VERSION "created by canmatrix"

NS_ :

BS_:

BU_: User ADM_PC_LL25 ADM_PC_BC25 ADM_PC_BP25 ADM_PC_BI25

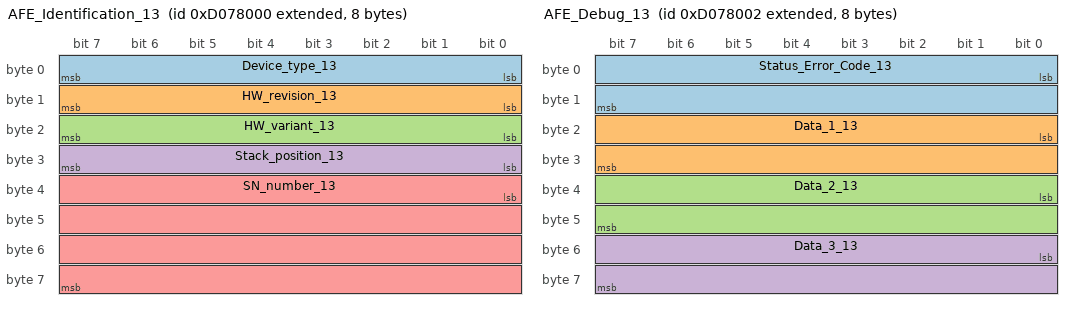
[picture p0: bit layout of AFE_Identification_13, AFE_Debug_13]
BO_ 2366078976 AFE_Identification_13: 8 ADM_PC_BP25
 SG_ Device_type_13 : 0|8@1+ (1,0) [0|255] "" Vector__XXX
 SG_ HW_revision_13 : 8|8@1+ (1,0) [0|255] "" Vector__XXX
 SG_ HW_variant_13 : 16|8@1+ (1,0) [0|255] "" Vector__XXX
 SG_ Stack_position_13 : 24|8@1+ (1,0) [0|255] "" Vector__XXX
 SG_ SN_number_13 : 32|32@1+ (1,0) [0|4294967295] "" Vector__XXX

BO_ 2366078977 AFE_FwInfo_13: 8 ADM_PC_BP25
 SG_ FW_info_mux_13 M : 56|8@1+ (1,0) [0|255] "" Vector__XXX
 SG_ FW_revision_0_13 m0 : 0|8@1+ (1,0) [0|255] "" Vector__XXX
 SG_ FW_revision_1_13 m0 : 8|8@1+ (1,0) [0|255] "" Vector__XXX
 SG_ FW_revision_2_13 m0 : 16|8@1+ (1,0) [0|255] "" Vector__XXX
 SG_ FW_revision_3_13 m0 : 24|8@1+ (1,0) [0|255] "" Vector__XXX
 SG_ FW_revision_4_13 m0 : 32|8@1+ (1,0) [0|255] "" Vector__XXX
 SG_ FW_revision_5_13 m0 : 40|8@1+ (1,0) [0|255] "" Vector__XXX
 SG_ FW_revision_6_13 m0 : 48|8@1+ (1,0) [0|255] "" Vector__XXX
 SG_ FW_revision_7_13 m1 : 0|8@1+ (1,0) [0|255] "" Vector__XXX
 SG_ FW_revision_8_13 m1 : 8|8@1+ (1,0) [0|255] "" Vector__XXX
 SG_ FW_revision_9_13 m1 : 16|8@1+ (1,0) [0|255] "" Vector__XXX
 SG_ FW_revision_10_13 m1 : 24|8@1+ (1,0) [0|255] "" Vector__XXX
 SG_ FW_revision_11_13 m1 : 32|8@1+ (1,0) [0|255] "" Vector__XXX
 SG_ FW_revision_12_13 m1 : 40|8@1+ (1,0) [0|255] "" Vector__XXX
 SG_ FW_revision_13_13 m1 : 48|8@1+ (1,0) [0|255] "" Vector__XXX
 SG_ FW_datecode_0_13 m2 : 0|8@1+ (1,0) [0|255] "" Vector__XXX
 SG_ FW_datecode_1_13 m2 : 8|8@1+ (1,0) [0|255] "" Vector__XXX
 SG_ FW_datecode_2_13 m2 : 16|8@1+ (1,0) [0|255] "" Vector__XXX
 SG_ FW_datecode_3_13 m2 : 24|8@1+ (1,0) [0|255] "" Vector__XXX
 SG_ FW_datecode_4_13 m2 : 32|8@1+ (1,0) [0|255] "" Vector__XXX
 SG_ FW_datecode_5_13 m2 : 40|8@1+ (1,0) [0|255] "" Vector__XXX
 SG_ FW_datecode_6_13 m2 : 48|8@1+ (1,0) [0|255] "" Vector__XXX
 SG_ FW_datecode_7_13 m3 : 0|8@1+ (1,0) [0|255] "" Vector__XXX
 SG_ FW_datecode_8_13 m3 : 8|8@1+ (1,0) [0|255] "" Vector__XXX
 SG_ FW_datecode_9_13 m3 : 16|8@1+ (1,0) [0|255] "" Vector__XXX
 SG_ FW_datecode_10_13 m3 : 24|8@1+ (1,0) [0|255] "" Vector__XXX
 SG_ FW_datecode_11_13 m3 : 32|8@1+ (1,0) [0|255] "" Vector__XXX
 SG_ FW_datecode_12_13 m3 : 40|8@1+ (1,0) [0|255] "" Vector__XXX
 SG_ FW_datecode_13_13 m3 : 48|8@1+ (1,0) [0|255] "" Vector__XXX

BO_ 2366078989 _AFE_Boot_FwInfo_13: 8 ADM_PC_BP25
 SG_ Boot_FW_info_mux_13 M : 56|8@1+ (1,0) [0|255] "" Vector__XXX
 SG_ FW_revision_0_13 m0 : 0|8@1+ (1,0) [0|255] "" Vector__XXX
 SG_ FW_revision_1_13 m0 : 8|8@1+ (1,0) [0|255] "" Vector__XXX
 SG_ FW_revision_2_13 m0 : 16|8@1+ (1,0) [0|255] "" Vector__XXX
 SG_ FW_revision_3_13 m0 : 24|8@1+ (1,0) [0|255] "" Vector__XXX
 SG_ FW_revision_4_13 m0 : 32|8@1+ (1,0) [0|255] "" Vector__XXX
 SG_ FW_revision_5_13 m0 : 40|8@1+ (1,0) [0|255] "" Vector__XXX
 SG_ FW_revision_6_13 m0 : 48|8@1+ (1,0) [0|255] "" Vector__XXX
 SG_ FW_revision_7_13 m1 : 0|8@1+ (1,0) [0|255] "" Vector__XXX
 SG_ FW_revision_8_13 m1 : 8|8@1+ (1,0) [0|255] "" Vector__XXX
 SG_ FW_revision_9_13 m1 : 16|8@1+ (1,0) [0|255] "" Vector__XXX
 SG_ FW_revision_10_13 m1 : 24|8@1+ (1,0) [0|255] "" Vector__XXX
 SG_ FW_revision_11_13 m1 : 32|8@1+ (1,0) [0|255] "" Vector__XXX
 SG_ FW_revision_12_13 m1 : 40|8@1+ (1,0) [0|255] "" Vector__XXX
 SG_ FW_revision_13_13 m1 : 48|8@1+ (1,0) [0|255] "" Vector__XXX
 SG_ FW_datecode_0_13 m2 : 0|8@1+ (1,0) [0|255] "" Vector__XXX
 SG_ FW_datecode_1_13 m2 : 8|8@1+ (1,0) [0|255] "" Vector__XXX
 SG_ FW_datecode_2_13 m2 : 16|8@1+ (1,0) [0|255] "" Vector__XXX
 SG_ FW_datecode_3_13 m2 : 24|8@1+ (1,0) [0|255] "" Vector__XXX
 SG_ FW_datecode_4_13 m2 : 32|8@1+ (1,0) [0|255] "" Vector__XXX
 SG_ FW_datecode_5_13 m2 : 40|8@1+ (1,0) [0|255] "" Vector__XXX
 SG_ FW_datecode_6_13 m2 : 48|8@1+ (1,0) [0|255] "" Vector__XXX
 SG_ FW_datecode_7_13 m3 : 0|8@1+ (1,0) [0|255] "" Vector__XXX
 SG_ FW_datecode_8_13 m3 : 8|8@1+ (1,0) [0|255] "" Vector__XXX
 SG_ FW_datecode_9_13 m3 : 16|8@1+ (1,0) [0|255] "" Vector__XXX
 SG_ FW_datecode_10_13 m3 : 24|8@1+ (1,0) [0|255] "" Vector__XXX
 SG_ FW_datecode_11_13 m3 : 32|8@1+ (1,0) [0|255] "" Vector__XXX
 SG_ FW_datecode_12_13 m3 : 40|8@1+ (1,0) [0|255] "" Vector__XXX
 SG_ FW_datecode_13_13 m3 : 48|8@1+ (1,0) [0|255] "" Vector__XXX

BO_ 2366078978 AFE_Debug_13: 8 ADM_PC_BP25
 SG_ Status_Error_Code_13 : 0|16@1+ (1,0) [0|65535] "" Vector__XXX
 SG_ Data_1_13 : 16|16@1+ (1,0) [0|65535] "" Vector__XXX
 SG_ Data_2_13 : 32|16@1+ (1,0) [0|65535] "" Vector__XXX
 SG_ Data_3_13 : 48|16@1+ (1,0) [0|65535] "" Vector__XXX

BO_ 2366078983 AFE_Status_13: 8 ADM_PC_BP25
 SG_ Running_13 : 0|1@1+ (1,0) [0|1] "" Vector__XXX
 SG_ PWM_13 : 1|1@1+ (1,0) [0|1] "" Vector__XXX
 SG_ Current_dc_loop_mode_13 : 2|1@1+ (1,0) [0|1] "" Vector__XXX
 SG_ Current_ac_loop_mode_13 : 3|1@1+ (1,0) [0|1] "" Vector__XXX
 SG_ Buck_13 : 5|1@1+ (1,0) [0|1] "" Vector__XXX
 SG_ Boost_13 : 6|1@1+ (1,0) [0|1] "" Vector__XXX
 SG_ Precharge_dc_buck_mode_13 : 7|1@1+ (1,0) [0|1] "" Vector__XXX
 SG_ Precharge_dc_boost_mode_13 : 8|1@1+ (1,0) [0|1] "" Vector__XXX
 SG_ Rectifier_3ph_13 : 9|1@1+ (1,0) [0|1] "" Vector__XXX
 SG_ Stack_mode_13 : 10|1@1+ (1,0) [0|1] "" Vector__XXX
 SG_ Master_13 : 11|1@1+ (1,0) [0|1] "" Vector__XXX
 SG_ Slave_13 : 12|1@1+ (1,0) [0|1] "" Vector__XXX
 SG_ Inverter_1ph_13 : 13|1@1+ (1,0) [0|1] "" Vector__XXX
 SG_ Boost_Neutral_13 : 14|1@1+ (1,0) [0|1] "" Vector__XXX
 SG_ Rectifier_1ph_13 : 15|1@1+ (1,0) [0|1] "" Vector__XXX
 SG_ Inverter_3ph_13 : 16|1@1+ (1,0) [0|1] "" Vector__XXX
 SG_ Ready_13 : 17|1@1+ (1,0) [0|1] "" Vector__XXX
 SG_ Inverter_1ph_Sync_13 : 18|1@1+ (1,0) [0|1] "" Vector__XXX
 SG_ Neutral_13 : 19|1@1+ (1,0) [0|1] "" Vector__XXX
 SG_ Rectifier_1ph_Buck_13 : 20|1@1+ (1,0) [0|1] "" Vector__XXX
 SG_ Inverter_1ph_Boost_13 : 21|1@1+ (1,0) [0|1] "" Vector__XXX
 SG_ Rectifier_distributed_13 : 22|1@1+ (1,0) [0|1] "" Vector__XXX
 SG_ MPPT_buck_13 : 23|1@1+ (1,0) [0|1] "" Vector__XXX
 SG_ MPPT_boost_13 : 24|1@1+ (1,0) [0|1] "" Vector__XXX
 SG_ Buck_2p_float_13 : 25|1@1+ (1,0) [0|1] "" Vector__XXX
 SG_ Inverter_1ph_Distributed_13 : 26|1@1+ (1,0) [0|1] "" Vector__XXX

BO_ 2366078982 AFE_Faults_13: 3 ADM_PC_BP25
 SG_ Protection_trip_internal_13 : 0|1@1+ (1,0) [0|1] "" Vector__XXX
 SG_ Protection_trip_external_13 : 1|1@1+ (1,0) [0|1] "" Vector__XXX
 SG_ Phase_U_overcurrent_13 : 2|1@1+ (1,0) [0|1] "" Vector__XXX
 SG_ Phase_U_overvoltage_13 : 3|1@1+ (1,0) [0|1] "" Vector__XXX
 SG_ Phase_U_undervoltage_13 : 4|1@1+ (1,0) [0|1] "" Vector__XXX
 SG_ Phase_V_overvoltage_13 : 5|1@1+ (1,0) [0|1] "" Vector__XXX
 SG_ Phase_V_undervoltage_13 : 6|1@1+ (1,0) [0|1] "" Vector__XXX
 SG_ Phase_V_overcurrent_13 : 7|1@1+ (1,0) [0|1] "" Vector__XXX
 SG_ Phase_W_overvoltage_13 : 8|1@1+ (1,0) [0|1] "" Vector__XXX
 SG_ Phase_W_undervoltage_13 : 9|1@1+ (1,0) [0|1] "" Vector__XXX
 SG_ Phase_W_overcurrent_13 : 10|1@1+ (1,0) [0|1] "" Vector__XXX
 SG_ DC_undervoltage_13 : 11|1@1+ (1,0) [0|1] "" Vector__XXX
 SG_ DC_overvoltage_13 : 12|1@1+ (1,0) [0|1] "" Vector__XXX
 SG_ MOSFET_overtemperature_13 : 13|1@1+ (1,0) [0|1] "" Vector__XXX
 SG_ Inductor_overtemperature_13 : 14|1@1+ (1,0) [0|1] "" Vector__XXX
 SG_ Keep_Alive_not_served_13 : 15|1@1+ (1,0) [0|1] "" Vector__XXX
 SG_ PLL_not_locked_13 : 16|1@1+ (1,0) [0|1] "" Vector__XXX
 SG_ NFO_13 : 20|1@1+ (1,0) [0|1] "" Vector__XXX
 SG_ Measurement_system_failure_13 : 21|1@1+ (1,0) [0|1] "" Vector__XXX
 SG_ EEPROM_failure_13 : 22|1@1+ (1,0) [0|1] "" Vector__XXX
 SG_ System_13 : 23|1@1+ (1,0) [0|1] "" Vector__XXX

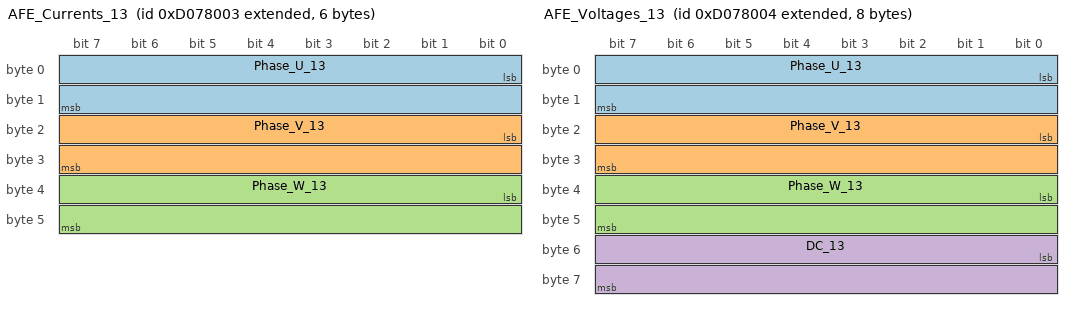
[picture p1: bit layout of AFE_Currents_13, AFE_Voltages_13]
BO_ 2366078979 AFE_Currents_13: 6 ADM_PC_BP25
 SG_ Phase_U_13 : 0|16@1- (0.01,0) [-327.68|327.67] "A" Vector__XXX
 SG_ Phase_V_13 : 16|16@1- (0.01,0) [-327.68|327.67] "A" Vector__XXX
 SG_ Phase_W_13 : 32|16@1- (0.01,0) [-327.68|327.67] "A" Vector__XXX

BO_ 2366078992 AFE_DC_Bus_current_13: 2 ADM_PC_BP25
 SG_ Bus_current_13 : 0|16@1- (0.01,0) [-327.68|327.67] "A" Vector__XXX

BO_ 2366078990 _AFE_Broadcast_13: 8 ADM_PC_BP25
 SG_ Diagnostics_Index_13 M : 56|8@1+ (1,0) [0|255] "" Vector__XXX
 SG_ Phase_U_13 m1 : 8|16@1- (0.01,0) [-327.68|327.67] "A" ADM_PC_BP25
 SG_ Phase_V_13 m1 : 24|16@1- (0.01,0) [-327.68|327.67] "A" ADM_PC_BP25
 SG_ Phase_W_13 m1 : 40|16@1- (0.01,0) [-327.68|327.67] "A" ADM_PC_BP25
 SG_ Stack_position_13 : 0|5@1+ (1,0) [0|31] "" ADM_PC_BP25
 SG_ Group_ID_13 : 5|3@1+ (1,0) [0|7] "" ADM_PC_BP25

BO_ 2366078980 AFE_Voltages_13: 8 ADM_PC_BP25
 SG_ Phase_U_13 : 0|16@1- (0.1,0) [-3276.8|3276.7] "V" Vector__XXX
 SG_ Phase_V_13 : 16|16@1- (0.1,0) [-3276.8|3276.7] "V" Vector__XXX
 SG_ Phase_W_13 : 32|16@1- (0.1,0) [-3276.8|3276.7] "V" Vector__XXX
 SG_ DC_13 : 48|16@1- (0.1,0) [-3276.8|3276.7] "V" Vector__XXX

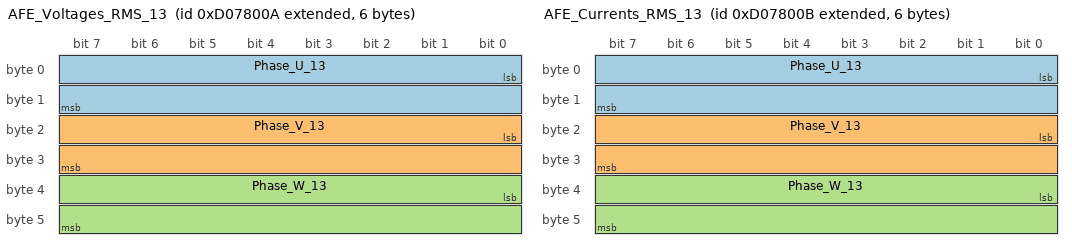
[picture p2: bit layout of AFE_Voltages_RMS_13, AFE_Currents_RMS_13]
BO_ 2366078986 AFE_Voltages_RMS_13: 6 ADM_PC_BP25
 SG_ Phase_U_13 : 0|16@1+ (0.1,0) [0|6553.5] "V" Vector__XXX
 SG_ Phase_V_13 : 16|16@1+ (0.1,0) [0|6553.5] "V" Vector__XXX
 SG_ Phase_W_13 : 32|16@1+ (0.1,0) [0|6553.5] "V" Vector__XXX

BO_ 2366078987 AFE_Currents_RMS_13: 6 ADM_PC_BP25
 SG_ Phase_U_13 : 0|16@1+ (0.01,0) [0.00|655.35] "A" Vector__XXX
 SG_ Phase_V_13 : 16|16@1+ (0.01,0) [0.00|655.35] "A" Vector__XXX
 SG_ Phase_W_13 : 32|16@1+ (0.01,0) [0.00|655.35] "A" Vector__XXX

BO_ 2366078988 AFE_Mains_13: 4 ADM_PC_BP25
 SG_ Frequency_13 : 0|16@1+ (0.01,0) [0.00|655.35] "Hz" Vector__XXX
 SG_ Phase_13 : 16|16@1- (0.1,0) [-3276.8|3276.7] "Deg." Vector__XXX

BO_ 2366078981 AFE_Temperatures_13: 4 ADM_PC_BP25
 SG_ Temp_Bridge_13 : 0|16@1- (0.01,0) [-327.68|327.67] "°C" Vector__XXX
 SG_ Temp_Inductors_13 : 16|16@1- (0.01,0) [-327.68|327.67] "°C" Vector__XXX

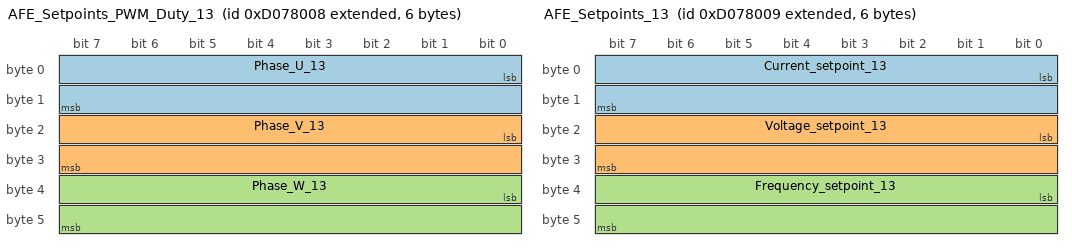
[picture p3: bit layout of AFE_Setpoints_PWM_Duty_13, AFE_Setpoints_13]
BO_ 2366078984 AFE_Setpoints_PWM_Duty_13: 6 ADM_PC_BP25
 SG_ Phase_U_13 : 0|16@1+ (0.001525902,0) [0E-009|99.999987570] "%" Vector__XXX
 SG_ Phase_V_13 : 16|16@1+ (0.001525902,0) [0E-009|99.999987570] "%" Vector__XXX
 SG_ Phase_W_13 : 32|16@1+ (0.001525902,0) [0E-009|99.999987570] "%" Vector__XXX

BO_ 2366078985 AFE_Setpoints_13: 6 ADM_PC_BP25
 SG_ Current_setpoint_13 : 0|16@1- (0.01,0) [-327.68|327.67] "A" Vector__XXX
 SG_ Voltage_setpoint_13 : 16|16@1+ (0.1,0) [0|6553.5] "V" Vector__XXX
 SG_ Frequency_setpoint_13 : 32|16@1+ (0.01,0) [0.00|655.35] "Hz" Vector__XXX

BO_ 2366046304 AFE_Keep_Alive_13: 1 User
 SG_ Keep_Alive_Enable_13 : 0|1@1+ (1,0) [0|1] "" ADM_PC_BP25

BO_ 2366046272 AFE_Mode_Control_13: 8 User
 SG_ Converter_ON_13 : 0|1@1+ (1,0) [0|1] "" ADM_PC_BP25
 SG_ PWM_ON_13 : 1|1@1+ (1,0) [0|1] "" ADM_PC_BP25
 SG_ DC_Current_feedback_ON_13 : 2|1@1+ (1,0) [0|1] "" ADM_PC_BP25
 SG_ AC_Current_feedback_ON_13 : 3|1@1+ (1,0) [0|1] "" ADM_PC_BP25
 SG_ Buck_ON_13 : 5|1@1+ (1,0) [0|1] "" ADM_PC_BP25
 SG_ Boost_ON_13 : 6|1@1+ (1,0) [0|1] "" ADM_PC_BP25
 SG_ Rectifier_3ph_ON_13 : 9|1@1+ (1,0) [0|1] "" ADM_PC_BP25
 SG_ Inverter_1ph_ON_13 : 10|1@1+ (1,0) [0|1] "" ADM_PC_BP25
 SG_ Rectifier_1ph_ON_13 : 11|1@1+ (1,0) [0|1] "" ADM_PC_BP25
 SG_ Boost_Neutral_ON_13 : 12|1@1+ (1,0) [0|1] "" ADM_PC_BP25
 SG_ Inverter_3ph_ON_13 : 13|1@1+ (1,0) [0|1] "" ADM_PC_BP25
 SG_ Inverter_1ph_Sync_ON_13 : 14|1@1+ (1,0) [0|1] "" ADM_PC_BP25
 SG_ Neutral_ON_13 : 15|1@1+ (1,0) [0|1] "" ADM_PC_BP25
 SG_ Rectifier_1ph_Buck_ON_13 : 16|1@1+ (1,0) [0|1] "" ADM_PC_BP25
 SG_ Inverter_1ph_Boost_ON_13 : 17|1@1+ (1,0) [0|1] "" ADM_PC_BP25
 SG_ Rectifier_Distributed_ON_13 : 18|1@1+ (1,0) [0|1] "" ADM_PC_BP25
 SG_ MPPT_buck_ON_13 : 19|1@1+ (1,0) [0|1] "" ADM_PC_BP25
 SG_ MPPT_boost_ON_13 : 20|1@1+ (1,0) [0|1] "" ADM_PC_BP25
 SG_ Buck_2p_float_ON_13 : 21|1@1+ (1,0) [0|1] "" ADM_PC_BP25
 SG_ Inverter_1ph_Distributed_ON_13 : 22|1@1+ (1,0) [0|1] "" ADM_PC_BP25

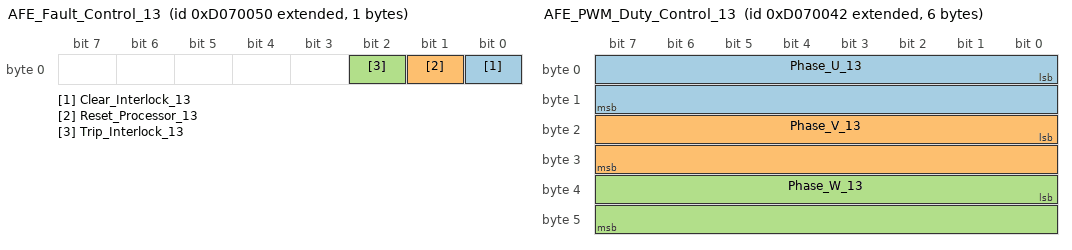
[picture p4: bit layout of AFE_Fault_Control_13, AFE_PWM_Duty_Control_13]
BO_ 2366046288 AFE_Fault_Control_13: 1 User
 SG_ Clear_Interlock_13 : 0|1@1+ (1,0) [0|1] "" ADM_PC_BP25
 SG_ Reset_Processor_13 : 1|1@1+ (1,0) [0|1] "" ADM_PC_BP25
 SG_ Trip_Interlock_13 : 2|1@1+ (1,0) [0|1] "" ADM_PC_BP25

BO_ 2366046273 AFE_Reactive_Current_Setpoint_Co: 2 User
 SG_ Reactive_current_setpoint_13 : 0|16@1- (0.01,0) [-150|150] "A" ADM_PC_BP25

BO_ 2366046274 AFE_PWM_Duty_Control_13: 6 User
 SG_ Phase_U_13 : 0|16@1+ (0.001525902,0) [0E-009|99.999987570] "%" ADM_PC_BP25
 SG_ Phase_V_13 : 16|16@1+ (0.001525902,0) [0E-009|99.999987570] "%" ADM_PC_BP25
 SG_ Phase_W_13 : 32|16@1+ (0.001525902,0) [0E-009|99.999987570] "%" ADM_PC_BP25

BO_ 2366046275 AFE_Current_Setpoint_Control_13: 2 User
 SG_ Current_setpoint_13 : 0|16@1- (0.01,0) [-150|150] "A" ADM_PC_BP25

BO_ 2366046276 AFE_Voltage_Setpoint_Control_13: 2 User
 SG_ Voltage_setpoint_13 : 0|16@1+ (0.1,0) [0|1500] "V" ADM_PC_BP25

BO_ 2366046280 AFE_Frequency_Setpoint_Control_1: 2 User
 SG_ Frequency_setpoint_13 : 0|16@1+ (0.01,0) [40|70] "Hz" ADM_PC_BP25

BO_ 2366046281 AFE_Phase_Setpoint_Control_13: 2 User
 SG_ Phase_setpoint_13 : 0|16@1+ (1,0) [0|360] "deg" ADM_PC_BP25

BO_ 2366046320 AFE_Rectifier_Setpoint_Control_1: 8 User
 SG_ Voltage_setpoint_2_13 : 0|16@1+ (0.1,0) [0|1500] "V" ADM_PC_BP25
 SG_ Current_setpoint_2_13 : 16|16@1- (0.01,0) [-150|150] "A" ADM_PC_BP25

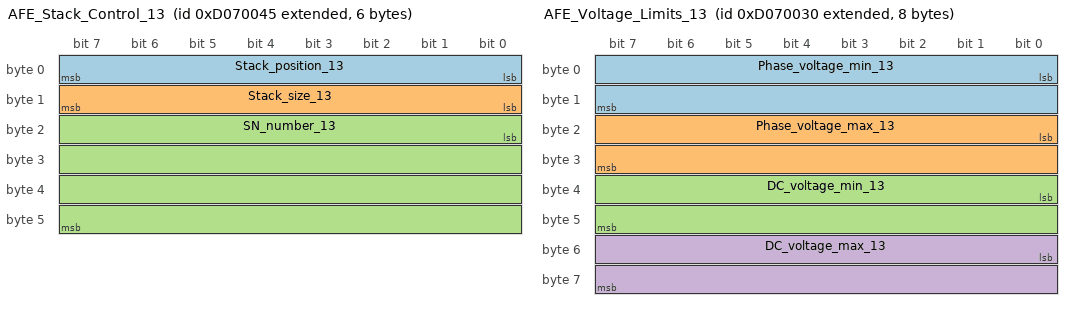
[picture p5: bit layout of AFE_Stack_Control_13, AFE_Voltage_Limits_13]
BO_ 2366046277 AFE_Stack_Control_13: 6 User
 SG_ Stack_position_13 : 0|8@1+ (1,0) [0|255] "" ADM_PC_BP25
 SG_ Stack_size_13 : 8|8@1+ (1,0) [0|255] "" ADM_PC_BP25
 SG_ SN_number_13 : 16|32@1+ (1,0) [0|4294967295] "" ADM_PC_BP25

BO_ 2366046256 AFE_Voltage_Limits_13: 8 User
 SG_ Phase_voltage_min_13 : 0|16@1- (0.1,0) [0|3276.7] "V" ADM_PC_BP25
 SG_ Phase_voltage_max_13 : 16|16@1- (0.1,0) [-3276.8|850] "V" ADM_PC_BP25
 SG_ DC_voltage_min_13 : 32|16@1- (0.1,0) [0|3276.7] "V" ADM_PC_BP25
 SG_ DC_voltage_max_13 : 48|16@1- (0.1,0) [-3276.8|850] "V" ADM_PC_BP25

BO_ 2366046257 AFE_Current_Limits_13: 4 User
 SG_ Phase_current_min_13 : 0|16@1- (0.01,0) [-60|60] "A" ADM_PC_BP25
 SG_ Phase_current_max_13 : 16|16@1- (0.01,0) [-60|60] "A" ADM_PC_BP25

BO_ 2366046284 AFE_Group_Control_13: 1 User
 SG_ Group_ID_13 : 0|8@1+ (1,0) [0|255] "" ADM_PC_BP25

BO_ 2366078991 AFE_Group_Info_13: 1 ADM_PC_BP25
 SG_ Group_ID_13 : 0|8@1+ (1,0) [0|255] "" Vector__XXX

BO_ 2366046305 AFE_System_Flags_Control_13: 8 User
 SG_ Factory_mode_13 : 0|1@1+ (1,0) [0|1] "" ADM_PC_BP25
 SG_ Silent_CAN_mode_13 : 1|1@1+ (1,0) [0|1] "" ADM_PC_BP25

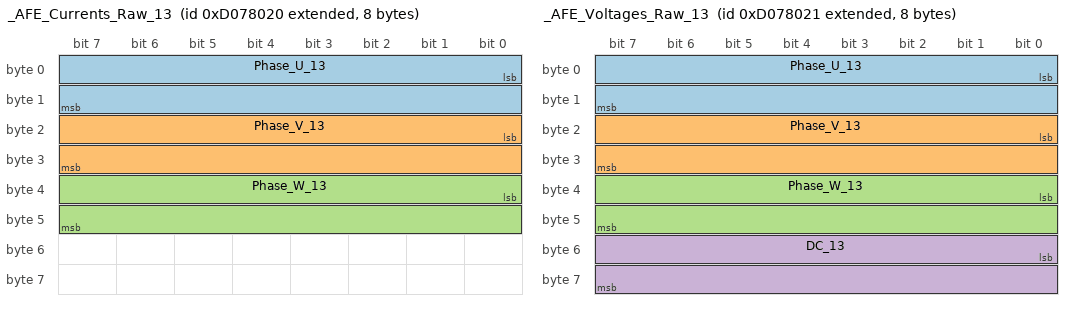
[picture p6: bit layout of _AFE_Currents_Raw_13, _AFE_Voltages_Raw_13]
BO_ 2366079008 _AFE_Currents_Raw_13: 8 ADM_PC_BP25
 SG_ Phase_U_13 : 0|16@1- (1,0) [-32768|32767] "" Vector__XXX
 SG_ Phase_V_13 : 16|16@1- (1,0) [-32768|32767] "" Vector__XXX
 SG_ Phase_W_13 : 32|16@1- (1,0) [-32768|32767] "" Vector__XXX

BO_ 2366079009 _AFE_Voltages_Raw_13: 8 ADM_PC_BP25
 SG_ Phase_U_13 : 0|16@1- (1,0) [-32768|32767] "" Vector__XXX
 SG_ Phase_V_13 : 16|16@1- (1,0) [-32768|32767] "" Vector__XXX
 SG_ Phase_W_13 : 32|16@1- (1,0) [-32768|32767] "" Vector__XXX
 SG_ DC_13 : 48|16@1- (1,0) [-32768|32767] "" Vector__XXX

BO_ 2366046282 _AFE_ADC_Calibration_Mode_13: 1 User
 SG_ Calibration_Index_13 M : 2|5@1+ (1,0) [0|31] "" Vector__XXX
 SG_ Current_U_13 m1 : 0|2@1+ (1,0) [0|3] "" ADM_PC_BP25
 SG_ Current_V_13 m2 : 0|2@1+ (1,0) [0|3] "" ADM_PC_BP25
 SG_ Current_W_13 m3 : 0|2@1+ (1,0) [0|3] "" ADM_PC_BP25
 SG_ Voltage_U_13 m4 : 0|2@1+ (1,0) [0|3] "" ADM_PC_BP25
 SG_ Voltage_V_13 m5 : 0|2@1+ (1,0) [0|3] "" ADM_PC_BP25
 SG_ Voltage_W_13 m6 : 0|2@1+ (1,0) [0|3] "" ADM_PC_BP25
 SG_ Voltage_DC_13 m7 : 0|2@1+ (1,0) [0|3] "" ADM_PC_BP25
 SG_ start_13 : 7|1@1+ (1,0) [0|1] "" ADM_PC_BP25

BO_ 2366046283 _AFE_ADC_Calibration_Setpoint_13: 3 User
 SG_ Calibration_Index_13 M : 16|5@1+ (1,0) [0|31] "" Vector__XXX
 SG_ Current_U_13 m1 : 0|16@1- (0.01,0) [-100|100] "A" ADM_PC_BP25
 SG_ Current_V_13 m2 : 0|16@1- (0.01,0) [-100|100] "A" ADM_PC_BP25
 SG_ Current_W_13 m3 : 0|16@1- (0.01,0) [-100|100] "A" ADM_PC_BP25
 SG_ Voltage_U_13 m4 : 0|16@1+ (0.1,0) [0|1500] "V" ADM_PC_BP25
 SG_ Voltage_V_13 m5 : 0|16@1+ (0.1,0) [0|1500] "V" ADM_PC_BP25
 SG_ Voltage_W_13 m6 : 0|16@1+ (0.1,0) [0|1500] "V" ADM_PC_BP25
 SG_ Voltage_DC_13 m7 : 0|16@1+ (0.1,0) [0|1500] "V" ADM_PC_BP25
 SG_ point_13 : 21|3@1+ (1,0) [0|7] "" ADM_PC_BP25

BO_ 2366046278 _AFE_Calibration_Offset_Update_1: 6 User
 SG_ Calibration_Index_13 M : 16|16@1+ (1,0) [0|65535] "" Vector__XXX
 SG_ Current_U_13 m0 : 0|16@1- (1,0) [-32768|32767] "ADC Counts" ADM_PC_BP25
 SG_ Current_V_13 m1 : 0|16@1- (1,0) [-32768|32767] "ADC Counts" ADM_PC_BP25
 SG_ Current_W_13 m2 : 0|16@1- (1,0) [-32768|32767] "ADC Counts" ADM_PC_BP25
 SG_ Voltage_U_13 m3 : 0|16@1- (1,0) [-32768|32767] "ADC Counts" ADM_PC_BP25
 SG_ Voltage_V_13 m4 : 0|16@1- (1,0) [-32768|32767] "ADC Counts" ADM_PC_BP25
 SG_ Voltage_W_13 m5 : 0|16@1- (1,0) [-32768|32767] "ADC Counts" ADM_PC_BP25
 SG_ Voltage_DC_13 m6 : 0|16@1- (1,0) [-32768|32767] "ADC Counts" ADM_PC_BP25
 SG_ CRC_13 : 32|16@1+ (1,0) [0|65535] "-" ADM_PC_BP25

BO_ 2366046279 _AFE_Calibration_Scale_Update_13: 6 User
 SG_ Calibration_Index_13 M : 16|16@1+ (1,0) [0|65535] "" Vector__XXX
 SG_ Current_U_13 m0 : 0|16@1- (0.0000152587890625,0) [-0.5000000000000000|0.4999847412109375] "scale = 1.0 + value" ADM_PC_BP25
 SG_ Current_V_13 m1 : 0|16@1- (0.0000152587890625,0) [-0.5000000000000000|0.4999847412109375] "scale = 1.0 + value" ADM_PC_BP25
 SG_ Current_W_13 m2 : 0|16@1- (0.0000152587890625,0) [-0.5000000000000000|0.4999847412109375] "scale = 1.0 + value" ADM_PC_BP25
 SG_ Voltage_U_13 m3 : 0|16@1- (0.0000152587890625,0) [-0.5000000000000000|0.4999847412109375] "scale = 1.0 + value" ADM_PC_BP25
 SG_ Voltage_V_13 m4 : 0|16@1- (0.0000152587890625,0) [-0.5000000000000000|0.4999847412109375] "scale = 1.0 + value" ADM_PC_BP25
 SG_ Voltage_W_13 m5 : 0|16@1- (0.0000152587890625,0) [-0.5000000000000000|0.4999847412109375] "scale = 1.0 + value" ADM_PC_BP25
 SG_ Voltage_DC_13 m6 : 0|16@1- (0.0000152587890625,0) [-0.5000000000000000|0.4999847412109375] "scale = 1.0 + value" ADM_PC_BP25
 SG_ CRC_13 : 32|16@1+ (1,0) [0|65535] "-" ADM_PC_BP25

BO_ 2366079057 _AFE_Calibration_Adc_Scale_13: 6 ADM_PC_BP25
 SG_ Adc_Index_13 M : 32|16@1+ (1,0) [0|65535] "" Vector__XXX
 SG_ Current_U_13 m0 : 0|32@1+ (1,0) [0|4294967295] "1 / adc_bins" User
 SG_ Current_V_13 m1 : 0|32@1+ (1,0) [0|4294967295] "1 / adc_bins" User
 SG_ Current_W_13 m2 : 0|32@1+ (1,0) [0|4294967295] "1 / adc_bins" User
 SG_ Voltage_U_13 m3 : 0|32@1+ (1,0) [0|4294967295] "1 / adc_bins" User
 SG_ Voltage_V_13 m4 : 0|32@1+ (1,0) [0|4294967295] "1 / adc_bins" User
 SG_ Voltage_W_13 m5 : 0|32@1+ (1,0) [0|4294967295] "1 / adc_bins" User
 SG_ Voltage_DC_13 m6 : 0|32@1+ (1,0) [0|4294967295] "1 / adc_bins" User

BO_ 2366079058 _AFE_Calibration_Adc_Fs_13: 6 ADM_PC_BP25
 SG_ Adc_Index_13 M : 32|16@1+ (1,0) [0|65535] "" Vector__XXX
 SG_ Current_U_13 m0 : 0|32@1+ (1,0) [0|4294967295] "Fullscale" User
 SG_ Current_V_13 m1 : 0|32@1+ (1,0) [0|4294967295] "Fullscale" User
 SG_ Current_W_13 m2 : 0|32@1+ (1,0) [0|4294967295] "Fullscale" User
 SG_ Voltage_U_13 m3 : 0|32@1+ (1,0) [0|4294967295] "Fullscale" User
 SG_ Voltage_V_13 m4 : 0|32@1+ (1,0) [0|4294967295] "Fullscale" User
 SG_ Voltage_W_13 m5 : 0|32@1+ (1,0) [0|4294967295] "Fullscale" User
 SG_ Voltage_DC_13 m6 : 0|32@1+ (1,0) [0|4294967295] "Fullscale" User

BO_ 2366079059 _AFE_Calibration_Adc_Offset_13: 4 ADM_PC_BP25
 SG_ Adc_Index_13 M : 16|16@1+ (1,0) [0|65535] "" Vector__XXX
 SG_ Current_U_13 m0 : 0|16@1- (1,0) [-32768|32767] "-" User
 SG_ Current_V_13 m1 : 0|16@1- (1,0) [-32768|32767] "-" User
 SG_ Current_W_13 m2 : 0|16@1- (1,0) [-32768|32767] "-" User
 SG_ Voltage_U_13 m3 : 0|16@1- (1,0) [-32768|32767] "-" User
 SG_ Voltage_V_13 m4 : 0|16@1- (1,0) [-32768|32767] "-" User
 SG_ Voltage_W_13 m5 : 0|16@1- (1,0) [-32768|32767] "-" User
 SG_ Voltage_DC_13 m6 : 0|16@1- (1,0) [-32768|32767] "-" User

BO_ 2366079060 _AFE_Calibration_Adc_Gain_13: 4 ADM_PC_BP25
 SG_ Adc_Index_13 M : 16|16@1+ (1,0) [0|65535] "" Vector__XXX
 SG_ Current_U_13 m0 : 0|16@1- (1,0) [-32768|32767] "-" User
 SG_ Current_V_13 m1 : 0|16@1- (1,0) [-32768|32767] "-" User
 SG_ Current_W_13 m2 : 0|16@1- (1,0) [-32768|32767] "-" User
 SG_ Voltage_U_13 m3 : 0|16@1- (1,0) [-32768|32767] "-" User
 SG_ Voltage_V_13 m4 : 0|16@1- (1,0) [-32768|32767] "-" User
 SG_ Voltage_W_13 m5 : 0|16@1- (1,0) [-32768|32767] "-" User
 SG_ Voltage_DC_13 m6 : 0|16@1- (1,0) [-32768|32767] "-" User

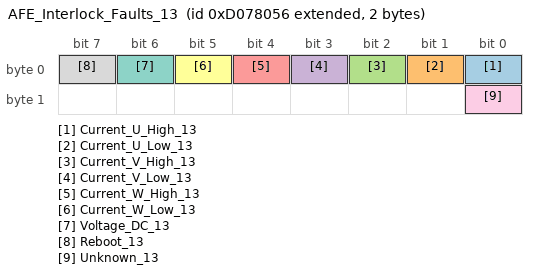
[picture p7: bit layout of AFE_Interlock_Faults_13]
BO_ 2366079062 AFE_Interlock_Faults_13: 2 ADM_PC_BP25
 SG_ Current_U_High_13 : 0|1@1+ (1,0) [0|1] "" Vector__XXX
 SG_ Current_U_Low_13 : 1|1@1+ (1,0) [0|1] "" Vector__XXX
 SG_ Current_V_High_13 : 2|1@1+ (1,0) [0|1] "" Vector__XXX
 SG_ Current_V_Low_13 : 3|1@1+ (1,0) [0|1] "" Vector__XXX
 SG_ Current_W_High_13 : 4|1@1+ (1,0) [0|1] "" Vector__XXX
 SG_ Current_W_Low_13 : 5|1@1+ (1,0) [0|1] "" Vector__XXX
 SG_ Voltage_DC_13 : 6|1@1+ (1,0) [0|1] "" Vector__XXX
 SG_ Reboot_13 : 7|1@1+ (1,0) [0|1] "" Vector__XXX
 SG_ Unknown_13 : 8|1@1+ (1,0) [0|1] "" Vector__XXX

BO_TX_BU_ 2366046272 : User,ADM_PC_LL25,ADM_PC_BC25,ADM_PC_BI25;
BO_TX_BU_ 2366046275 : User,ADM_PC_LL25,ADM_PC_BC25,ADM_PC_BI25;
BO_TX_BU_ 2366046276 : User,ADM_PC_LL25,ADM_PC_BC25,ADM_PC_BI25;
CM_ BO_ 2366078976  "Identification of the device";
CM_ BO_ 2366078977  "Git revision of the DSP firmware";
CM_ BO_ 2366078989  "Git revision of the bootloader firmware.";
CM_ BO_ 2366078978  "Values for debugging of HW/SW problems";
CM_ BO_ 2366078983  "Status bitfield";
CM_ BO_ 2366078982  "Fault bitfield";
CM_ BO_ 2366078979  "Current of phases U, V, W";
CM_ BO_ 2366078992  "Current of of the DC Bus";
CM_ BO_ 2366078990  "All AFEs will listen to this message";
CM_ BO_ 2366078987  "RMS Current of phases U, V, W";
CM_ BO_ 2366078988  "Three-Phase mains health (frequency, phase...)";
CM_ BO_ 2366078981  "Readouts of the module temperature sensors";
CM_ BO_ 2366078984  "Setpoints";
CM_ BO_ 2366078985  "Setpoints";
CM_ BO_ 2366046304  "Keep alive ping message. ";
CM_ BO_ 2366046272  "Operation Mode control: sets the converter operation mode";
CM_ BO_ 2366046288  "Fault Control: actions to clear faults and reset the system";
CM_ BO_ 2366046273  "Reactive power setpoint control.";
CM_ BO_ 2366046274  "PWM duty cycle control";
CM_ BO_ 2366046275  "Current setpoint control";
CM_ BO_ 2366046276  "Voltage setpoint control";
CM_ BO_ 2366046280  "Frequency setpoint control";
CM_ BO_ 2366046281  "Phase setpoint control";
CM_ BO_ 2366046320  "Additional voltage and current setpoints in single-phase rectifier and inverter control modes.";
CM_ BO_ 2366046277  "PFC stack control";
CM_ BO_ 2366046256  "Set the input and output voltage limits (minimum and maximum)";
CM_ BO_ 2366046257  "Set the output current limits (mminimum and maximum)";
CM_ BO_ 2366046284  "Set the Group ID of the device";
CM_ BO_ 2366078991  "Contains the Group ID of the device";
CM_ BO_ 2366046305  "Control the system flags";
CM_ BO_ 2366079008  "Current of phases A and B";
CM_ BO_ 2366079009  "Current of phases A and B";
CM_ BO_ 2366046282  "Automatic ADC calibration.";
CM_ BO_ 2366046283  "Setpoint for automatic ADC calibration.";
CM_ BO_ 2366046278  "Update of the calibration table for offsets.";
CM_ BO_ 2366046279  "Update of the calibration table for scales.";
CM_ BO_ 2366079057  "
                Adc scale (resolution) value of readouts.
            ";
CM_ BO_ 2366079058  "
                Adc fullscale value of readouts.
            ";
CM_ BO_ 2366079059  "
                Readout of ADC calibration data (offset) from EEPROM.
            ";
CM_ BO_ 2366079060  "
                Readout of ADC calibration data (gain) from EEPROM.
            ";
CM_ BO_ 2366079062  "Fault bitfield";

CM_ SG_ 2366078976 Device_type_13 "The device identification field, uniquely identifies the sender in the network";
CM_ SG_ 2366078976 HW_revision_13 "The hardware revision number";
CM_ SG_ 2366078976 HW_variant_13 "The DSP firmware revision number";
CM_ SG_ 2366078976 Stack_position_13 "Position of the module within the stack";
CM_ SG_ 2366078976 SN_number_13 "Unique module serial number";
CM_ SG_ 2366078977 FW_revision_0_13 "Character 0";
CM_ SG_ 2366078977 FW_revision_1_13 "Character 1";
CM_ SG_ 2366078977 FW_revision_2_13 "Character 2";
CM_ SG_ 2366078977 FW_revision_3_13 "Character 3";
CM_ SG_ 2366078977 FW_revision_4_13 "Character 3";
CM_ SG_ 2366078977 FW_revision_5_13 "Character 3";
CM_ SG_ 2366078977 FW_revision_6_13 "Character 3";
CM_ SG_ 2366078977 FW_revision_7_13 "Character 7";
CM_ SG_ 2366078977 FW_revision_8_13 "Character 8";
CM_ SG_ 2366078977 FW_revision_9_13 "Character 9";
CM_ SG_ 2366078977 FW_revision_10_13 "Character 10";
CM_ SG_ 2366078977 FW_revision_11_13 "Character 11";
CM_ SG_ 2366078977 FW_revision_12_13 "Character 12";
CM_ SG_ 2366078977 FW_revision_13_13 "Character 13";
CM_ SG_ 2366078977 FW_datecode_0_13 "Character 0";
CM_ SG_ 2366078977 FW_datecode_1_13 "Character 1";
CM_ SG_ 2366078977 FW_datecode_2_13 "Character 2";
CM_ SG_ 2366078977 FW_datecode_3_13 "Character 3";
CM_ SG_ 2366078977 FW_datecode_4_13 "Character 3";
CM_ SG_ 2366078977 FW_datecode_5_13 "Character 3";
CM_ SG_ 2366078977 FW_datecode_6_13 "Character 3";
CM_ SG_ 2366078977 FW_datecode_7_13 "Character 7";
CM_ SG_ 2366078977 FW_datecode_8_13 "Character 8";
CM_ SG_ 2366078977 FW_datecode_9_13 "Character 9";
CM_ SG_ 2366078977 FW_datecode_10_13 "Character 10";
CM_ SG_ 2366078977 FW_datecode_11_13 "Character 11";
CM_ SG_ 2366078977 FW_datecode_12_13 "Character 12";
CM_ SG_ 2366078977 FW_datecode_13_13 "Character 13";
CM_ SG_ 2366078989 FW_revision_0_13 "Character 0";
CM_ SG_ 2366078989 FW_revision_1_13 "Character 1";
CM_ SG_ 2366078989 FW_revision_2_13 "Character 2";
CM_ SG_ 2366078989 FW_revision_3_13 "Character 3";
CM_ SG_ 2366078989 FW_revision_4_13 "Character 3";
CM_ SG_ 2366078989 FW_revision_5_13 "Character 3";
CM_ SG_ 2366078989 FW_revision_6_13 "Character 3";
CM_ SG_ 2366078989 FW_revision_7_13 "Character 7";
CM_ SG_ 2366078989 FW_revision_8_13 "Character 8";
CM_ SG_ 2366078989 FW_revision_9_13 "Character 9";
CM_ SG_ 2366078989 FW_revision_10_13 "Character 10";
CM_ SG_ 2366078989 FW_revision_11_13 "Character 11";
CM_ SG_ 2366078989 FW_revision_12_13 "Character 12";
CM_ SG_ 2366078989 FW_revision_13_13 "Character 13";
CM_ SG_ 2366078989 FW_datecode_0_13 "Character 0";
CM_ SG_ 2366078989 FW_datecode_1_13 "Character 1";
CM_ SG_ 2366078989 FW_datecode_2_13 "Character 2";
CM_ SG_ 2366078989 FW_datecode_3_13 "Character 3";
CM_ SG_ 2366078989 FW_datecode_4_13 "Character 3";
CM_ SG_ 2366078989 FW_datecode_5_13 "Character 3";
CM_ SG_ 2366078989 FW_datecode_6_13 "Character 3";
CM_ SG_ 2366078989 FW_datecode_7_13 "Character 7";
CM_ SG_ 2366078989 FW_datecode_8_13 "Character 8";
CM_ SG_ 2366078989 FW_datecode_9_13 "Character 9";
CM_ SG_ 2366078989 FW_datecode_10_13 "Character 10";
CM_ SG_ 2366078989 FW_datecode_11_13 "Character 11";
CM_ SG_ 2366078989 FW_datecode_12_13 "Character 12";
CM_ SG_ 2366078989 FW_datecode_13_13 "Character 13";
CM_ SG_ 2366078978 Status_Error_Code_13 "Main status / error code as defined in errno/errno.h";
CM_ SG_ 2366078978 Data_1_13 "Additional information for the error/status";
CM_ SG_ 2366078978 Data_2_13 "Additional information for the error/status";
CM_ SG_ 2366078978 Data_3_13 "Additional information for the error/status";
CM_ SG_ 2366078983 Running_13 "Indicates if converter is running.";
CM_ SG_ 2366078983 PWM_13 "Indicates if converter is in PWM control mode.";
CM_ SG_ 2366078983 Current_dc_loop_mode_13 "Indicates if the current DC loop is enabled.";
CM_ SG_ 2366078983 Current_ac_loop_mode_13 "Indicates if the current AC loop is enabled.";
CM_ SG_ 2366078983 Buck_13 "Indicates if converter is in buck control mode.";
CM_ SG_ 2366078983 Boost_13 "Indicates if converter is in boost control mode.";
CM_ SG_ 2366078983 Precharge_dc_buck_mode_13 "Indicates if the precharge DC mode is enabled - buck direction.";
CM_ SG_ 2366078983 Precharge_dc_boost_mode_13 "Indicates if the precharge DC mode is enabled - boost direction.";
CM_ SG_ 2366078983 Rectifier_3ph_13 "Indicates if converter is in three-phase rectifier control mode.";
CM_ SG_ 2366078983 Stack_mode_13 "Indicates if converter is operating in stack mode.";
CM_ SG_ 2366078983 Master_13 "Indicates if converter is master in the stack.";
CM_ SG_ 2366078983 Slave_13 "Indicates if converter is slave in the stack.";
CM_ SG_ 2366078983 Inverter_1ph_13 "Indicates if converter is in single-phase inverter control mode.";
CM_ SG_ 2366078983 Boost_Neutral_13 "Indicates if converter is in boost control mode with neutral generation.";
CM_ SG_ 2366078983 Rectifier_1ph_13 "Indicates if converter is in single-phase rectifier control mode.";
CM_ SG_ 2366078983 Inverter_3ph_13 "Indicates if converter is in three-phase inverter control mode.";
CM_ SG_ 2366078983 Ready_13 "Indicates if converter is ready for operation.";
CM_ SG_ 2366078983 Inverter_1ph_Sync_13 "Single-phase inverter control mode with phase synchronization.";
CM_ SG_ 2366078983 Neutral_13 "Open-loop neutral generation.";
CM_ SG_ 2366078983 Rectifier_1ph_Buck_13 "Single-phase rectifier with buck on one leg.";
CM_ SG_ 2366078983 Inverter_1ph_Boost_13 "Single-phase inverter with boost on one leg.";
CM_ SG_ 2366078983 Rectifier_distributed_13 "Not available at the moment";
CM_ SG_ 2366078983 MPPT_buck_13 "Not available at the moment";
CM_ SG_ 2366078983 MPPT_boost_13 "Not available at the moment";
CM_ SG_ 2366078983 Buck_2p_float_13 "Buck in phases L1 and L2. Phase L3 is left floating (high impedance)";
CM_ SG_ 2366078983 Inverter_1ph_Distributed_13 "Single-phase inverter mode  distributed";
CM_ SG_ 2366078982 Protection_trip_internal_13 "This flagg is asserted if the interlock is open due to an internal fault condition (self-protection)";
CM_ SG_ 2366078982 Protection_trip_external_13 "This flag is asserted if the interlock is open due to an external condition received in the module.";
CM_ SG_ 2366078982 Phase_U_overcurrent_13 "Indicates an overcurrent event on Phase U. The overcurrent event is triggered when the measured phase current is over the programmed current limit.";
CM_ SG_ 2366078982 Phase_U_overvoltage_13 "Indicates an overvoltage event on Phase U. The overvoltage event is triggered when the measured phase voltage is over the programmed voltage limit.";
CM_ SG_ 2366078982 Phase_U_undervoltage_13 "Indicates an undervoltage event on Phase U. The overvoltage event is triggered when the measured phase voltage is over the programmed voltage limit.";
CM_ SG_ 2366078982 Phase_V_overvoltage_13 "Indicates an overvoltage event on Phase V. The overvoltage event is triggered when the measured phase voltage is over the programmed voltage limit.";
CM_ SG_ 2366078982 Phase_V_undervoltage_13 "Indicates an undervoltage event on Phase U. The overvoltage event is triggered when the measured phase voltage is over the programmed voltage limit.";
CM_ SG_ 2366078982 Phase_V_overcurrent_13 "Indicates an overcurrent event on Phase U. The overcurrent event is triggered when the measured phase current is over the programmed current limit.";
CM_ SG_ 2366078982 Phase_W_overvoltage_13 "Indicates an overvoltage event on Phase U. The overvoltage event is triggered when the measured phase voltage is over the programmed voltage limit.";
CM_ SG_ 2366078982 Phase_W_undervoltage_13 "Indicates an undervoltage event on Phase U. The overvoltage event is triggered when the measured phase voltage is over the programmed voltage limit.";
CM_ SG_ 2366078982 Phase_W_overcurrent_13 "Indicates an overcurrent event on Phase U. The overcurrent event is triggered when the measured phase current is over the programmed current limit.";
CM_ SG_ 2366078982 DC_undervoltage_13 "DC bus undervoltage condition. The undervoltage condition is asserted when the measured dc bus voltage is under the programmed voltage limit.";
CM_ SG_ 2366078982 DC_overvoltage_13 "DC bus overvoltage condition. The overvoltage condition is asserted when the measured dc bus voltage is over the programmed voltage limit.";
CM_ SG_ 2366078982 MOSFET_overtemperature_13 "This flag is asserted when the temperature of the MOSFET block is too high.";
CM_ SG_ 2366078982 Inductor_overtemperature_13 "This flag is asserted when the temperature of the inductor block is too high.";
CM_ SG_ 2366078982 Keep_Alive_not_served_13 "The Keep Alive feature is enabled but it was not served with the periodic message.";
CM_ SG_ 2366078982 PLL_not_locked_13 "Flag asserted when in rectifier modes, the PLL went out of lock condition";
CM_ SG_ 2366078982 Measurement_system_failure_13 "The voltages/currents measurement system is malfunctionning, and readouts are not guaranteed to be accurate.";
CM_ SG_ 2366078982 EEPROM_failure_13 "The configuration EEPROM failed to load or save the module configuration.";
CM_ SG_ 2366078979 Phase_U_13 "Phase current is the MOSFET loop current, in the branch U of the converter.";
CM_ SG_ 2366078979 Phase_V_13 "Phase current is the MOSFET loop current, in the branch V of the converter.";
CM_ SG_ 2366078979 Phase_W_13 "Phase current is the MOSFET loop current, in the branch W of the converter.";
CM_ SG_ 2366078992 Bus_current_13 "DC Bus current is possitive when current goes from input to output";
CM_ SG_ 2366078990 Phase_U_13 "Phase current is the MOSFET loop current, in the branch U of the converter.";
CM_ SG_ 2366078990 Phase_V_13 "Phase current is the MOSFET loop current, in the branch V of the converter.";
CM_ SG_ 2366078990 Phase_W_13 "Phase current is the MOSFET loop current, in the branch W of the converter.";
CM_ SG_ 2366078990 Stack_position_13 "Sender Stack position";
CM_ SG_ 2366078990 Group_ID_13 "Sender Group ID";
CM_ SG_ 2366078987 Phase_U_13 "RMS Phase current is the MOSFET loop current, in the branch U of the converter.";
CM_ SG_ 2366078987 Phase_V_13 "RMS Phase current is the MOSFET loop current, in the branch V of the converter.";
CM_ SG_ 2366078987 Phase_W_13 "RMS Phase current is the MOSFET loop current, in the branch W of the converter.";
CM_ SG_ 2366078988 Frequency_13 "Frequency of Three-Phase system";
CM_ SG_ 2366078988 Phase_13 "Phase of Three-Phase system";
CM_ SG_ 2366078981 Temp_Bridge_13 "Temperature of the MOSFET block";
CM_ SG_ 2366078981 Temp_Inductors_13 "Temperature of the inductors";
CM_ SG_ 2366078984 Phase_U_13 "The actual PWM duty cycle setpoint";
CM_ SG_ 2366078984 Phase_V_13 "The actual PWM duty cycle setpoint";
CM_ SG_ 2366078984 Phase_W_13 "The actual PWM duty cycle setpoint";
CM_ SG_ 2366078985 Current_setpoint_13 "The actual current setpoint";
CM_ SG_ 2366078985 Voltage_setpoint_13 "The actual voltage setpoint";
CM_ SG_ 2366078985 Frequency_setpoint_13 "The actual frequency setpoint";
CM_ SG_ 2366046304 Keep_Alive_Enable_13 "If set to 1, module will expect to receive this message every second repeatedly, or it will stop operation";
CM_ SG_ 2366046272 Converter_ON_13 "Enable the converter.";
CM_ SG_ 2366046272 PWM_ON_13 "Enable the PWM control mode.";
CM_ SG_ 2366046272 DC_Current_feedback_ON_13 "Enable the DC current loop";
CM_ SG_ 2366046272 AC_Current_feedback_ON_13 "Enable the AC current loop";
CM_ SG_ 2366046272 Buck_ON_13 "Enable the buck control mode.";
CM_ SG_ 2366046272 Boost_ON_13 "Enable the boost control mode.";
CM_ SG_ 2366046272 Rectifier_3ph_ON_13 "Enable the three-phase rectifier control mode.";
CM_ SG_ 2366046272 Inverter_1ph_ON_13 "Enable the single-phase inverter control mode.";
CM_ SG_ 2366046272 Rectifier_1ph_ON_13 "Enable the single-phase rectifier control mode.";
CM_ SG_ 2366046272 Boost_Neutral_ON_13 "Enable the boost control mode with neutral generation.";
CM_ SG_ 2366046272 Inverter_3ph_ON_13 "Enable the three-phase inverter control mode.";
CM_ SG_ 2366046272 Inverter_1ph_Sync_ON_13 "Single-phase inverter control mode with phase synchronization.";
CM_ SG_ 2366046272 Neutral_ON_13 "Open-loop neutral generation.";
CM_ SG_ 2366046272 Rectifier_1ph_Buck_ON_13 "Single-phase rectifier with buck on one leg.";
CM_ SG_ 2366046272 Inverter_1ph_Boost_ON_13 "Single-phase inverter with boost on one leg.";
CM_ SG_ 2366046272 Rectifier_Distributed_ON_13 "Single-phase (floating) distributed rectifier";
CM_ SG_ 2366046272 MPPT_buck_ON_13 "MPPT buck";
CM_ SG_ 2366046272 MPPT_boost_ON_13 "MPPT boost";
CM_ SG_ 2366046272 Buck_2p_float_ON_13 "Boost on L1 and L2. Floating L3 (high-impedance)";
CM_ SG_ 2366046272 Inverter_1ph_Distributed_ON_13 "Single-phase inverter mode distributed";
CM_ SG_ 2366046288 Clear_Interlock_13 "Clears the converter interlock";
CM_ SG_ 2366046288 Reset_Processor_13 "Reset the converter DSP";
CM_ SG_ 2366046288 Trip_Interlock_13 "Trip the inetrnal Interlock";
CM_ SG_ 2366046273 Reactive_current_setpoint_13 "This defines reactive current setpoint for 3-phase rectifier mode";
CM_ SG_ 2366046274 Phase_U_13 "The actual PWM duty cycle setpoint";
CM_ SG_ 2366046274 Phase_V_13 "The actual PWM duty cycle setpoint";
CM_ SG_ 2366046274 Phase_W_13 "The actual PWM duty cycle setpoint";
CM_ SG_ 2366046275 Current_setpoint_13 "Sets the output current setpoint. Active only when the current loop is enabled";
CM_ SG_ 2366046276 Voltage_setpoint_13 "Sets the output voltage setpoint. Active only when the voltage loop is enabled";
CM_ SG_ 2366046280 Frequency_setpoint_13 "Sets the frequency for single-phase and three-phase generator modes.";
CM_ SG_ 2366046281 Phase_setpoint_13 "Sets the phase for inverter control modes.";
CM_ SG_ 2366046277 Stack_position_13 "The converter position within the stack";
CM_ SG_ 2366046277 Stack_size_13 "How many PFC converters are in stack in total";
CM_ SG_ 2366046277 SN_number_13 "Unique module serial number";
CM_ SG_ 2366046256 Phase_voltage_min_13 "Minimum tolerated phase voltage";
CM_ SG_ 2366046256 Phase_voltage_max_13 "Maximum allowable phase voltage";
CM_ SG_ 2366046256 DC_voltage_min_13 "Minimum allowable dc voltage";
CM_ SG_ 2366046256 DC_voltage_max_13 "Maximum allowable dc voltage";
CM_ SG_ 2366046257 Phase_current_min_13 "Minimum allowable output current";
CM_ SG_ 2366046257 Phase_current_max_13 "Maximum allowable output current";
CM_ SG_ 2366046284 Group_ID_13 "Desired group ID for the device";
CM_ SG_ 2366078991 Group_ID_13 "Group ID of the device";
CM_ SG_ 2366046305 Factory_mode_13 "Customers MUST NOT USE this bit. If set to 1, module will enter in factory mode. ";
CM_ SG_ 2366046305 Silent_CAN_mode_13 "Customers MUST NOT USE this bit. If set to 1, module will enter in factory mode. ";
CM_ SG_ 2366046282 start_13 "Start automatic calibration. Multiplexer index must be 0!";
CM_ SG_ 2366046283 point_13 "Calibration point index.";
CM_ SG_ 2366046278 CRC_13 "Checksum of bytes 0 to 3, CRC-CCITT, corresponding to qChecksum (www.qt.io)";
CM_ SG_ 2366046279 CRC_13 "Checksum of bytes 0 to 3, CRC-CCITT, corresponding to qChecksum (www.qt.io)";
CM_ SG_ 2366079062 Current_U_High_13 "This flag is set if a hight current on U tripped the internal interlock";
CM_ SG_ 2366079062 Current_U_Low_13 "This flag is set if a low current on U tripped the internal interlock";
CM_ SG_ 2366079062 Current_V_High_13 "This flag is set if a hight current on V tripped the internal interlock";
CM_ SG_ 2366079062 Current_V_Low_13 "This flag is set if a low current on V tripped the internal interlock";
CM_ SG_ 2366079062 Current_W_High_13 "This flag is set if a hight current on W tripped the internal interlock";
CM_ SG_ 2366079062 Current_W_Low_13 "This flag is set if a low current on W tripped the internal interlock";
CM_ SG_ 2366079062 Voltage_DC_13 "This flag is set if a voltage on DC tripped the internal interlock";
CM_ SG_ 2366079062 Reboot_13 "This flag is set if a reboot tripped the internal interlock";
CM_ SG_ 2366079062 Unknown_13 "This flag the reason for the internal interlock is unknown";

BA_DEF_ BO_ "SystemMessageLongSymbol" STRING;

BA_ "SystemMessageLongSymbol" BO_ 2366046273 "AFE_Reactive_Current_Setpoint_Control_13";
BA_ "SystemMessageLongSymbol" BO_ 2366046280 "AFE_Frequency_Setpoint_Control_13";
BA_ "SystemMessageLongSymbol" BO_ 2366046320 "AFE_Rectifier_Setpoint_Control_13";
BA_ "SystemMessageLongSymbol" BO_ 2366046278 "_AFE_Calibration_Offset_Update_13";

VAL_ 2366078976 Device_type_13 7 "AFE";
VAL_ 2366078982 Protection_trip_internal_13 1 "fault";
VAL_ 2366078982 Protection_trip_external_13 1 "fault";
VAL_ 2366078982 Phase_U_overcurrent_13 1 "fault";
VAL_ 2366078982 Phase_U_overvoltage_13 1 "fault";
VAL_ 2366078982 Phase_U_undervoltage_13 1 "fault";
VAL_ 2366078982 Phase_V_overvoltage_13 1 "fault";
VAL_ 2366078982 Phase_V_undervoltage_13 1 "fault";
VAL_ 2366078982 Phase_V_overcurrent_13 1 "fault";
VAL_ 2366078982 Phase_W_overvoltage_13 1 "fault";
VAL_ 2366078982 Phase_W_undervoltage_13 1 "fault";
VAL_ 2366078982 Phase_W_overcurrent_13 1 "fault";
VAL_ 2366078982 DC_undervoltage_13 1 "fault";
VAL_ 2366078982 DC_overvoltage_13 1 "fault";
VAL_ 2366078982 MOSFET_overtemperature_13 1 "fault";
VAL_ 2366078982 Inductor_overtemperature_13 1 "fault";
VAL_ 2366078982 Keep_Alive_not_served_13 1 "fault";
VAL_ 2366078982 PLL_not_locked_13 1 "fault";
VAL_ 2366078982 NFO_13 1 "fault";
VAL_ 2366078982 Measurement_system_failure_13 1 "fault";
VAL_ 2366078982 EEPROM_failure_13 1 "fault";
VAL_ 2366078982 System_13 1 "fault";
VAL_ 2366079062 Current_U_High_13 1 "fault";
VAL_ 2366079062 Current_U_Low_13 1 "fault";
VAL_ 2366079062 Current_V_High_13 1 "fault";
VAL_ 2366079062 Current_V_Low_13 1 "fault";
VAL_ 2366079062 Current_W_High_13 1 "fault";
VAL_ 2366079062 Current_W_Low_13 1 "fault";
VAL_ 2366079062 Voltage_DC_13 1 "fault";
VAL_ 2366079062 Reboot_13 1 "fault";
VAL_ 2366079062 Unknown_13 1 "fault";
SIG_VALTYPE_ 2366079057 Current_U_13 : 1;
SIG_VALTYPE_ 2366079057 Current_V_13 : 1;
SIG_VALTYPE_ 2366079057 Current_W_13 : 1;
SIG_VALTYPE_ 2366079057 Voltage_U_13 : 1;
SIG_VALTYPE_ 2366079057 Voltage_V_13 : 1;
SIG_VALTYPE_ 2366079057 Voltage_W_13 : 1;
SIG_VALTYPE_ 2366079057 Voltage_DC_13 : 1;
SIG_VALTYPE_ 2366079058 Current_U_13 : 1;
SIG_VALTYPE_ 2366079058 Current_V_13 : 1;
SIG_VALTYPE_ 2366079058 Current_W_13 : 1;
SIG_VALTYPE_ 2366079058 Voltage_U_13 : 1;
SIG_VALTYPE_ 2366079058 Voltage_V_13 : 1;
SIG_VALTYPE_ 2366079058 Voltage_W_13 : 1;
SIG_VALTYPE_ 2366079058 Voltage_DC_13 : 1;
